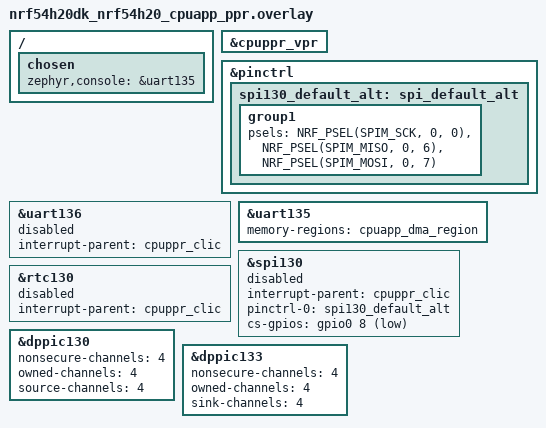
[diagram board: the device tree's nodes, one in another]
/*
 * Copyright (c) 2026 Nordic Semiconductor ASA
 *
 * SPDX-License-Identifier: LicenseRef-Nordic-5-Clause
 */

/ {
	chosen {
		zephyr,console = &uart135;
	};
};

&cpuppr_vpr {
	status = "okay";
};

&pinctrl {
	spi130_default_alt: spi_default_alt {
		group1 {
			psels = <NRF_PSEL(SPIM_SCK, 0, 0)>,
				<NRF_PSEL(SPIM_MISO, 0, 6)>,
				<NRF_PSEL(SPIM_MOSI, 0, 7)>;
		};
	};
};

/* Console uart for PPR for testing reason it's the UART typically used by the cpuapp. */
&uart136 {
	status = "reserved";
	interrupt-parent = <&cpuppr_clic>;
};

&uart135 {
	status = "okay";
	memory-regions = <&cpuapp_dma_region>;
};

sample_spi: &spi130 {
	status = "reserved";
	interrupt-parent = <&cpuppr_clic>;
	pinctrl-0 = <&spi130_default_alt>;
	pinctrl-names = "default";
	cs-gpios = <&gpio0 8 GPIO_ACTIVE_LOW>;
};

sample_rtc: &rtc130 {
	status = "reserved";
	interrupt-parent = <&cpuppr_clic>;
};

&dppic130 {
	status = "okay";
	nonsecure-channels = <4>;
	owned-channels = <4>;
	/* RTC130->SPI130 */
	source-channels = <4>;
};

&dppic133 {
	status = "okay";

	nonsecure-channels = <4>;
	owned-channels = <4>;
	/* SPI130<-RTC130/GRTC */
	sink-channels = <4>;
};
